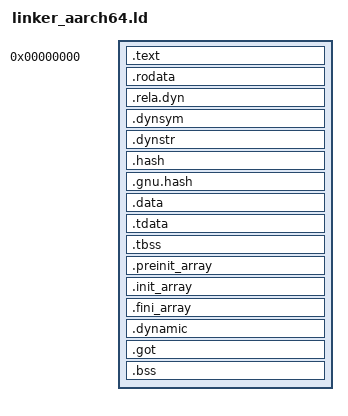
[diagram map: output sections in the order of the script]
OUTPUT_FORMAT(elf64-littleaarch64)
OUTPUT_ARCH(aarch64)
ENTRY(_start)

/* Position-independent: linked at 0, the kernel picks the load base and applies the
   RELATIVE relocations listed in .rela.dyn. */
PHDRS
{
    text PT_LOAD FLAGS(0x05);
    rodata PT_LOAD FLAGS(0x04);
    data PT_LOAD FLAGS(0x06);
    dynamic PT_DYNAMIC FLAGS(0x06);
    tls PT_TLS FLAGS(0x04);
}

SECTIONS
{
    . = 0;

    .text : {
        *(.text .text.*)
    } :text

    . = ALIGN(0x1000);

    .rodata : {
        *(.rodata .rodata.*)
    } :rodata

    .rela.dyn : {
        *(.rela.dyn .rela.*)
    } :rodata

    .dynsym : {
        *(.dynsym)
    } :rodata

    .dynstr : {
        *(.dynstr)
    } :rodata

    .hash : {
        *(.hash)
    } :rodata

    .gnu.hash : {
        *(.gnu.hash)
    } :rodata

    . = ALIGN(0x1000);

    .data : {
        *(.data .data.* .data.rel.ro .data.rel.ro.*)
    } :data

    /* The template each thread's thread-local block starts from: initial values, then the zeros
       .tbss stands for, which take no space in the file or the data segment. */
    .tdata : {
        *(.tdata .tdata.*)
    } :data :tls

    .tbss : {
        *(.tbss .tbss.*)
    } :data :tls

    /* Function pointers the C library's _start and exit call: global constructors and
       destructors. */
    .preinit_array : {
        PROVIDE_HIDDEN(__preinit_array_start = .);
        KEEP(*(.preinit_array))
        PROVIDE_HIDDEN(__preinit_array_end = .);
    } :data

    .init_array : {
        PROVIDE_HIDDEN(__init_array_start = .);
        KEEP(*(SORT_BY_INIT_PRIORITY(.init_array.*) SORT_BY_INIT_PRIORITY(.ctors.*)))
        KEEP(*(.init_array .ctors))
        PROVIDE_HIDDEN(__init_array_end = .);
    } :data

    .fini_array : {
        PROVIDE_HIDDEN(__fini_array_start = .);
        KEEP(*(SORT_BY_INIT_PRIORITY(.fini_array.*) SORT_BY_INIT_PRIORITY(.dtors.*)))
        KEEP(*(.fini_array .dtors))
        PROVIDE_HIDDEN(__fini_array_end = .);
    } :data

    .dynamic : {
        *(.dynamic)
    } :data :dynamic

    .got : {
        *(.got .got.*)
    } :data

    .bss : {
        *(.bss .bss.*)
        *(COMMON)
    } :data

    /DISCARD/ : {
        *(.eh_frame*)
        *(.note .note.*)
        *(.comment)
        *(.interp)
        *(.ARM.attributes)
    }
}
